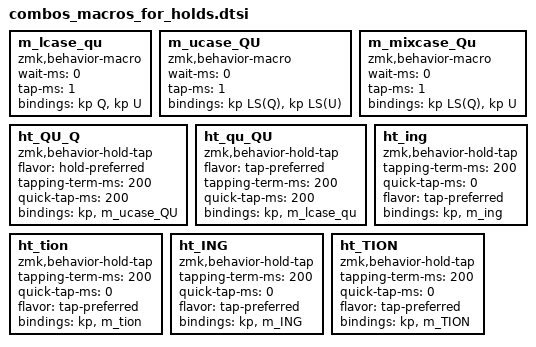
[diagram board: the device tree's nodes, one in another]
#include <dt-bindings/zmk/keys.h>

/*****************************************************************************************************
 *  COMBO and MACRO configurations
 *  General TODOs/ Opens:
 *  - [ ] (type/key-send) macro-ify some of these? (e.g. the Q/QU/Qu cases)
 *  - [ ] see if can use mod-morph for some of the hold-tap combos (e.g. qu/QU) instead of hold-tap;
 *      or even macro-morph? (since not really mods)
 *  - [ ] make C-macros to make this tidier
 *  - [ ] general timings; many never really dialed in (wait- tap- tapping-term- quick-tap-ms); )
 */


// --------------------
// Q / QU cases
// See Claude_working_notes.md for a full account of failed approaches before arriving here.
//
// Summary of what works:
//   tap          → "qu"   via m_lcase_qu (no shift involved)
//   hold         → "q"    via kp Q (the hold param)
//   shift + tap  → "QU"   (ZMK cannot suppress physical shift inside a macro — see notes)
//   &sk + tap    → "Qu"   use one-shot shift (&sk LSHFT) before tapping for mixed-case

// Q macros: --------------------
m_lcase_qu: m_lcase_qu {
    compatible = "zmk,behavior-macro";
    wait-ms = <0>;
    tap-ms = <1>;
    #binding-cells = <0>;
    bindings = <&kp Q>, <&kp U>;
};

m_ucase_QU: m_ucase_QU {
    compatible = "zmk,behavior-macro";
    wait-ms = <0>;
    tap-ms = <1>;
    #binding-cells = <0>;
    bindings = <&kp LS(Q)>, <&kp LS(U)>;
};

// m_mixcase_Qu: used by combo_qu_mixcase (P+QU chord). No physical shift held
// during a combo, so kp LS(Q)+kp U = "Qu" cleanly — no suppression needed.
m_mixcase_Qu: m_mixcase_Qu {
    compatible = "zmk,behavior-macro";
    wait-ms = <0>;
    tap-ms = <1>;
    #binding-cells = <0>;
    bindings = <&kp LS(Q)>, <&kp U>;
};

// CAP layer HT --------------------
ht_QU_Q: ht_QU_Q {
    compatible = "zmk,behavior-hold-tap";
    #binding-cells = <2>;
    flavor = "hold-preferred";
    tapping-term-ms = <200>;
    quick-tap-ms = <200>;
    bindings = <&kp>, <&m_ucase_QU>; // hold for Q (LS(Q)), tap for QU macro
};

// HOLD TAP: q | qu  — tap binding is m_lcase_qu directly (no mod-morph).
// Shift+tap gives "QU"; use &sk LSHFT before tap for "Qu". See Claude_working_notes.md.
ht_qu_QU: ht_qu_QU {
    compatible = "zmk,behavior-hold-tap";
    #binding-cells = <2>;
    flavor = "tap-preferred";
    tapping-term-ms = <200>;
    quick-tap-ms = <200>;
    bindings = <&kp>, <&m_lcase_qu>; // hold=kp (Q→"q"), tap="qu"
};



// ----------------------------------------------------------------------------------------------------
// ING / TION hold-taps: hold=kp (N5/N6), tap=macro
// NGM layer: m_ing/m_tion are shift-aware — physical shift held while tapping → "ING"/"TION"
// CAP layer: m_ING/m_TION always send uppercase (no physical shift on that layer)

ht_ing: ht_ing {
    compatible = "zmk,behavior-hold-tap";
    #binding-cells = <2>;
    tapping-term-ms = <200>;
    quick-tap-ms = <0>;
    flavor = "tap-preferred";
    bindings = <&kp>, <&m_ing>;
};
ht_tion: ht_tion {
    compatible = "zmk,behavior-hold-tap";
    #binding-cells = <2>;
    tapping-term-ms = <200>;
    quick-tap-ms = <0>;
    flavor = "tap-preferred";
    bindings = <&kp>, <&m_tion>;
};
ht_ING: ht_ING {
    compatible = "zmk,behavior-hold-tap";
    #binding-cells = <2>;
    tapping-term-ms = <200>;
    quick-tap-ms = <0>;
    flavor = "tap-preferred";
    bindings = <&kp>, <&m_ING>;
};
ht_TION: ht_TION {
    compatible = "zmk,behavior-hold-tap";
    #binding-cells = <2>;
    tapping-term-ms = <200>;
    quick-tap-ms = <0>;
    flavor = "tap-preferred";
    bindings = <&kp>, <&m_TION>;
};

// ----------------------------------------------------------------------------------------------------
// Hold=macro / tap=kp pairs: ordinal suffixes, time abbreviations, etc.
// Generates both the zmk,behavior-macro node (m_NAME) and the hold-tap wrapper (ht_NAME).
// ZMK finds behaviors by compatible string regardless of DTS block — both nodes live here in macros{}.
// To add/change an entry: edit macro_ht_data.dtsi only.

#define TAPPING_TERM_HT_MACRO 225

// Combined C macro: emits m_NAME (macro) + ht_NAME (hold-tap) in one shot.
#define HT_MACRO_ENTRY(NAME, ...) \
m_##NAME: m_##NAME { \
    compatible = "zmk,behavior-macro"; \
    wait-ms = <0>; \
    tap-ms = <1>; \
    #binding-cells = <0>; \
    bindings = __VA_ARGS__; \
}; \
ht_##NAME: ht_##NAME { \
    compatible = "zmk,behavior-hold-tap"; \
    #binding-cells = <2>; \
    tapping-term-ms = <TAPPING_TERM_HT_MACRO>; \
    quick-tap-ms = <0>; \
    flavor = "tap-preferred"; \
    bindings = <&m_##NAME>, <&kp>; \
};

#include "macro_ht_data.dtsi"
#undef HT_MACRO_ENTRY


